AUTOSAR XML (schema 4-2-2)
package /SystemSWC
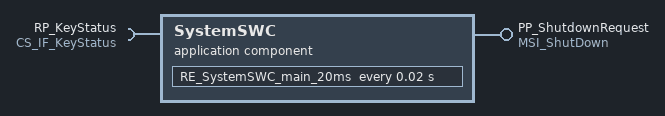
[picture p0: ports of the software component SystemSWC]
  application sw component type SystemSWC
    require port RP_KeyStatus: required-interface=CS_IF_KeyStatus
    provide port PP_ShutdownRequest: provided-interface=MSI_ShutDown
    behavior SwcInternalBehavior: data-type-mapping=[DataTypeMappingSet, MG_Shutdown_Mapping]
      timing event TE_RE_SystemSWC_main_20ms: start-on-event=RE_SystemSWC_main_20ms, period=0.02
      runnable RE_SystemSWC_main_20ms
        mode switch point ModeSwitchPoint_0: mode-group=PP_ShutdownRequest.MDGP_MSI_ShutDown
        sync call SynchronousServerCallPoint_0: operation=RP_KeyStatus.KeyStatus
